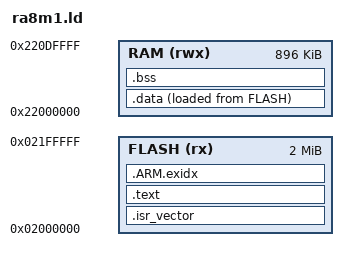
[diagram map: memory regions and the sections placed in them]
/* ra8m1.ld: code flash @0x02000000 (2M), SRAM @0x22000000 (896K) of the RA8M1 */
ENTRY(Reset_Handler)
MEMORY
{
    FLASH (rx)  : ORIGIN = 0x02000000, LENGTH = 2048K
    RAM   (rwx) : ORIGIN = 0x22000000, LENGTH = 896K
}
_estack = ORIGIN(RAM) + LENGTH(RAM);
SECTIONS
{
    .isr_vector : { KEEP(*(.isr_vector)) } > FLASH
    .text : { *(.text*) *(.rodata*) . = ALIGN(4); } > FLASH
    .ARM.exidx : { *(.ARM.exidx*) } > FLASH
    _sidata = LOADADDR(.data);
    .data : { _sdata = .; *(.data*) . = ALIGN(4); _edata = .; } > RAM AT > FLASH
    .bss (NOLOAD) : { _sbss = .; *(.bss*) *(COMMON) . = ALIGN(8); _ebss = .; } > RAM
}
